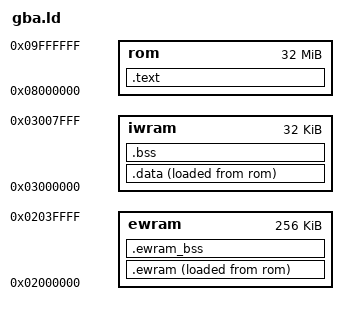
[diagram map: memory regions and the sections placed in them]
OUTPUT_FORMAT("elf32-littlearm")
OUTPUT_ARCH(arm)
ENTRY(_start)

MEMORY {
    rom   : ORIGIN = 0x08000000, LENGTH = 32M
    iwram : ORIGIN = 0x03000000, LENGTH = 32K
    ewram : ORIGIN = 0x02000000, LENGTH = 256K
}

__sp_irq = 0x03007FA0;
__sp_usr = 0x03007F00;

SECTIONS {
    .text : {
        KEEP(*(.crt0))
        *(.text .text.*)
        *(.rodata .rodata.*)
        . = ALIGN(4);
    } > rom

    .data : {
        __data_start = .;
        *(.iwram .iwram.*)
        *(.data .data.*)
        . = ALIGN(4);
        __data_end = .;
    } > iwram AT > rom
    __data_lma = LOADADDR(.data);

    .bss (NOLOAD) : {
        __bss_start = .;
        *(.bss .bss.*) *(COMMON)
        . = ALIGN(4);
        __bss_end = .;
    } > iwram

    .ewram : {
        __ewram_start = .;
        *(.ewram .ewram.*)
        . = ALIGN(4);
        __ewram_end = .;
    } > ewram AT > rom
    __ewram_lma = LOADADDR(.ewram);

    .ewram_bss (NOLOAD) : {
        __ewram_bss_start = .;
        *(.sbss .sbss.*)
        . = ALIGN(4);
        __ewram_bss_end = .;
    } > ewram

    /DISCARD/ : { *(.ARM.exidx*) *(.comment) }
}
